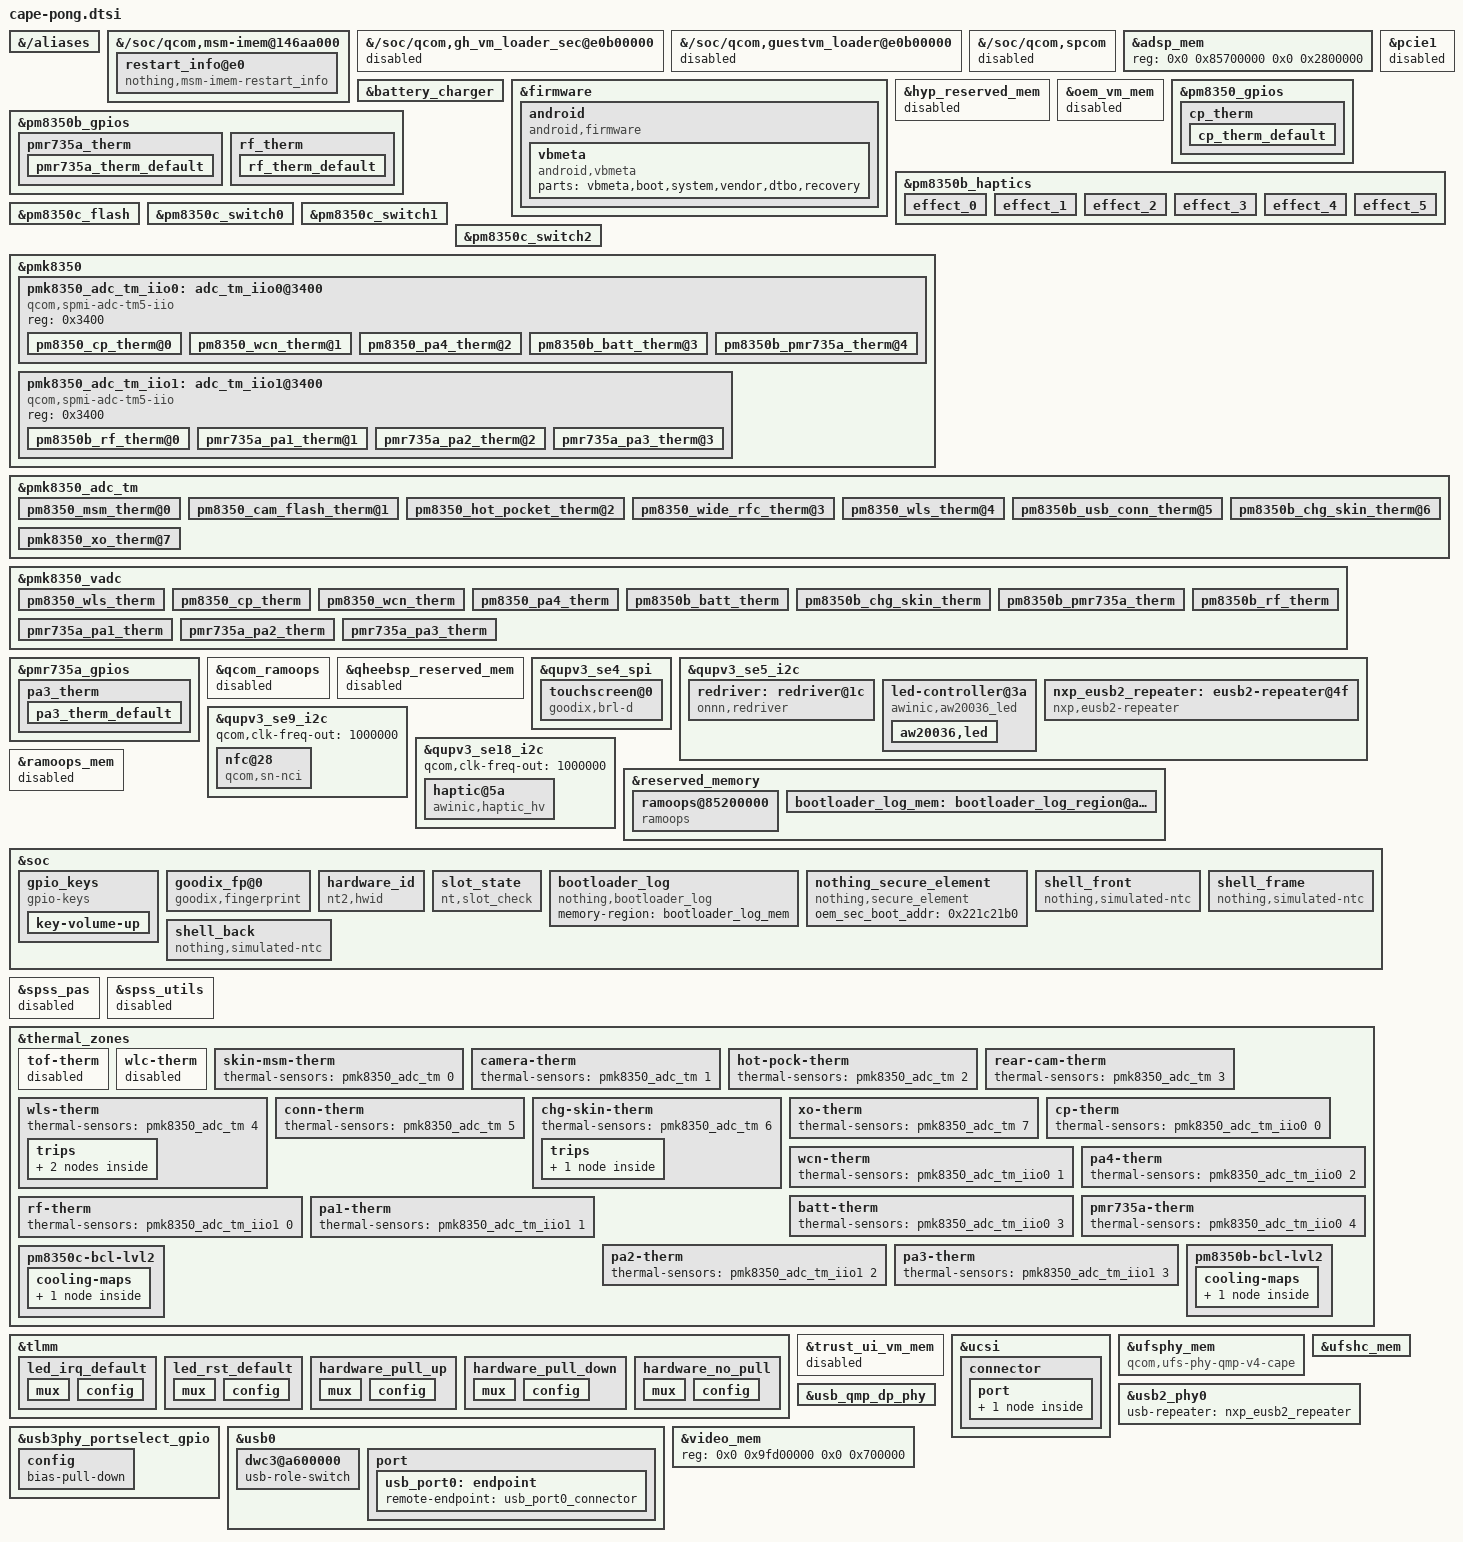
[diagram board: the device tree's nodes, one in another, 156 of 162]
// SPDX-License-Identifier: BSD-3-Clause
// SPDX-FileCopyrightText: 2026 The PenguinOS Project

#include <dt-bindings/gpio/gpio.h>
#include <dt-bindings/input/input.h>
#include <dt-bindings/phy/qcom,usb3-4nm-qmp-combo.h>

#include "cape-pmic-overlay.dtsi"
#include "waipio-pm8010-spmi.dtsi"
#include "waipio-thermal-overlay.dtsi"

#include "cape-pong-regulators.dtsi"

&{/aliases} {
	i2c0 = "/soc/qcom,qupv3_0_geni_se@9c0000/i2c@994000";
	i2c1 = "/soc/qcom,qupv3_1_geni_se@ac0000/i2c@a84000";
	i2c2 = "/soc/qcom,qupv3_1_geni_se@ac0000/i2c@a94000";
	i2c3 = "/soc/qcom,qupv3_2_geni_se@8c0000/i2c@88c000";
};

&{/soc/qcom,msm-imem@146aa000} {
	restart_info@e0 {
		compatible = "nothing,msm-imem-restart_info";
		reg = <0xe0 0x64>;
		info_size = <0x64>;
	};
};

/* No trusted UI VM on this board; its carveout is gone too */
&{/soc/qcom,gh_vm_loader_sec@e0b00000} {
	status = "disabled";
};

&{/soc/qcom,guestvm_loader@e0b00000} {
	status = "disabled";
};

&{/soc/qcom,spcom} {
	status = "disabled";
};

&adsp_mem {
	reg = <0x0 0x85700000 0x0 0x2800000>;
};

&battery_charger {
	qcom,thermal-mitigation = <9000000 8500000 8000000 7500000 7000000
				   6500000 6000000 5500000 5000000 4500000
				   4000000 3500000 3000000 2500000 2400000
				   2000000 1600000 1500000 1200000 1000000
				   500000 0>;
	qcom,wireless-fw-name = "idt9415.bin";
	#cooling-cells = <2>;
};

&firmware {
	android {
		compatible = "android,firmware";

		vbmeta {
			compatible = "android,vbmeta";
			parts = "vbmeta,boot,system,vendor,dtbo,recovery";
		};
	};
};

&hyp_reserved_mem {
	status = "disabled";
};

&oem_vm_mem {
	status = "disabled";
};

&pcie1 {
	status = "disabled";
};

&pm8350_gpios {
	cp_therm {
		cp_therm_default: cp_therm_default {
			pins = "gpio2";
			bias-high-impedance;
		};
	};
};

&pm8350b_gpios {
	pmr735a_therm {
		pmr735a_therm_default: pmr735a_therm_default {
			pins = "gpio3";
			bias-high-impedance;
		};
	};

	rf_therm {
		rf_therm_default: rf_therm_default {
			pins = "gpio4";
			bias-high-impedance;
		};
	};
};

&pm8350b_haptics {
	qcom,vmax-mv = <1300>;
	qcom,lra-period-us = <5880>;

	status = "okay";

	effect_0 {
		/* CLICK */
		qcom,wf-vmax-mv = <1800>;
		qcom,wf-pattern-period-us = <5880>;
	};

	effect_1 {
		/* DOUBLE_CLICK */
		qcom,wf-vmax-mv = <1800>;
		qcom,wf-pattern-period-us = <5880>;
	};

	effect_2 {
		/* TICK */
		qcom,wf-vmax-mv = <1800>;
		qcom,wf-pattern-period-us = <5880>;
	};

	effect_3 {
		/* THUD */
		qcom,wf-vmax-mv = <1800>;
		qcom,wf-pattern-period-us = <5880>;
	};

	effect_4 {
		/* POP */
		qcom,wf-vmax-mv = <1800>;
		qcom,wf-pattern-period-us = <5880>;
	};

	effect_5 {
		/* HEAVY CLICK */
		qcom,wf-vmax-mv = <1800>;
		qcom,wf-pattern-period-us = <5880>;
	};
};

&pm8350c_flash {
	status = "okay";
};

&pm8350c_switch0 {
	qcom,led-mask = <9>; /* Channels 1 & 4 */
	qcom,symmetry-en;
};

&pm8350c_switch1 {
	qcom,led-mask = <6>; /* Channels 2 & 3 */
	qcom,symmetry-en;
};

&pm8350c_switch2 {
	qcom,led-mask = <15>; /* All Channels */
	qcom,symmetry-en;
};

&pmk8350 {
	pmk8350_adc_tm_iio0: adc_tm_iio0@3400 {
		compatible = "qcom,spmi-adc-tm5-iio";
		reg = <0x3400>;
		#address-cells = <1>;
		#size-cells = <0>;
		#thermal-sensor-cells = <1>;

		pm8350_cp_therm@0 {
			reg = <0>;
			io-channels = <&pmk8350_vadc PM8350_ADC7_GPIO1_100K_PU>;
			qcom,ratiometric;
			qcom,hw-settle-time-us = <200>;
		};

		pm8350_wcn_therm@1 {
			reg = <1>;
			io-channels = <&pmk8350_vadc PM8350_ADC7_GPIO2_100K_PU>;
			qcom,ratiometric;
			qcom,hw-settle-time-us = <200>;
		};

		pm8350_pa4_therm@2 {
			reg = <2>;
			io-channels = <&pmk8350_vadc PM8350_ADC7_GPIO4_100K_PU>;
			qcom,ratiometric;
			qcom,hw-settle-time-us = <200>;
		};

		pm8350b_batt_therm@3 {
			reg = <3>;
			io-channels = <&pmk8350_vadc PM8350B_ADC7_AMUX_THM1_100K_PU>;
			qcom,ratiometric;
			qcom,hw-settle-time-us = <200>;
		};

		pm8350b_pmr735a_therm@4 {
			reg = <4>;
			io-channels = <&pmk8350_vadc PM8350B_ADC7_GPIO3_100K_PU>;
			qcom,ratiometric;
			qcom,hw-settle-time-us = <200>;
		};
	};

	pmk8350_adc_tm_iio1: adc_tm_iio1@3400 {
		compatible = "qcom,spmi-adc-tm5-iio";
		reg = <0x3400>;
		#address-cells = <1>;
		#size-cells = <0>;
		#thermal-sensor-cells = <1>;

		pm8350b_rf_therm@0 {
			reg = <0>;
			io-channels = <&pmk8350_vadc PM8350B_ADC7_GPIO4_100K_PU>;
			qcom,ratiometric;
			qcom,hw-settle-time-us = <200>;
		};

		pmr735a_pa1_therm@1 {
			reg = <1>;
			io-channels = <&pmk8350_vadc PMR735A_ADC7_GPIO1_100K_PU>;
			qcom,ratiometric;
			qcom,hw-settle-time-us = <200>;
		};

		pmr735a_pa2_therm@2 {
			reg = <2>;
			io-channels = <&pmk8350_vadc PMR735A_ADC7_GPIO2_100K_PU>;
			qcom,ratiometric;
			qcom,hw-settle-time-us = <200>;
		};

		pmr735a_pa3_therm@3 {
			reg = <3>;
			io-channels = <&pmk8350_vadc PMR735A_ADC7_GPIO3_100K_PU>;
			qcom,ratiometric;
			qcom,hw-settle-time-us = <200>;
		};
	};
};

/*
 * The ADC_TM5 driver wants reg to be the TM channel (0-7) and io-channels
 * per child, not the ADC channel number used by waipio-pmic-overlay.dtsi.
 */
&pmk8350_adc_tm {
	/delete-property/ io-channels;
	/delete-node/ pm8350_msm_therm;
	/delete-node/ pm8350_cam_flash_therm;
	/delete-node/ pm8350_hot_pocket_therm;
	/delete-node/ pm8350_wide_rfc_therm;
	/delete-node/ pm8350_rear_tof_therm;
	/delete-node/ pm8350b_usb_conn_therm;
	/delete-node/ pm8350b_wl_chg_therm;
	/delete-node/ pmk8350_xo_therm;

	pm8350_msm_therm@0 {
		reg = <0>;
		io-channels = <&pmk8350_vadc PM8350_ADC7_AMUX_THM1_100K_PU>;
		qcom,ratiometric;
		qcom,hw-settle-time-us = <200>;
	};

	pm8350_cam_flash_therm@1 {
		reg = <1>;
		io-channels = <&pmk8350_vadc PM8350_ADC7_AMUX_THM2_100K_PU>;
		qcom,ratiometric;
		qcom,hw-settle-time-us = <200>;
	};

	pm8350_hot_pocket_therm@2 {
		reg = <2>;
		io-channels = <&pmk8350_vadc PM8350_ADC7_AMUX_THM3_100K_PU>;
		qcom,ratiometric;
		qcom,hw-settle-time-us = <200>;
	};

	pm8350_wide_rfc_therm@3 {
		reg = <3>;
		io-channels = <&pmk8350_vadc PM8350_ADC7_AMUX_THM4_100K_PU>;
		qcom,ratiometric;
		qcom,hw-settle-time-us = <200>;
	};

	pm8350_wls_therm@4 {
		reg = <4>;
		io-channels = <&pmk8350_vadc PM8350_ADC7_AMUX_THM5_100K_PU>;
		qcom,ratiometric;
		qcom,hw-settle-time-us = <200>;
	};

	pm8350b_usb_conn_therm@5 {
		reg = <5>;
		io-channels = <&pmk8350_vadc PM8350B_ADC7_AMUX_THM4_100K_PU>;
		qcom,ratiometric;
		qcom,hw-settle-time-us = <200>;
	};

	pm8350b_chg_skin_therm@6 {
		reg = <6>;
		io-channels = <&pmk8350_vadc PM8350B_ADC7_GPIO2_100K_PU>;
		qcom,ratiometric;
		qcom,hw-settle-time-us = <200>;
	};

	pmk8350_xo_therm@7 {
		reg = <7>;
		io-channels = <&pmk8350_vadc PMK8350_ADC7_AMUX_THM1_100K_PU>;
		qcom,ratiometric;
		qcom,hw-settle-time-us = <200>;
	};
};

&pmk8350_vadc {
	pinctrl-0 = <&pm8350_rear_tof_therm_default &pmr735a_therm_default
		     &rf_therm_default &cp_therm_default &pa3_therm_default>;

	/delete-node/ pm8350_rear_tof_therm;
	/delete-node/ pm8350b_wl_chg_therm;

	pm8350_wls_therm {
		reg = <PM8350_ADC7_AMUX_THM5_100K_PU>;
		label = "pm8350_wls_therm";
		qcom,ratiometric;
		qcom,hw-settle-time = <200>;
		qcom,pre-scaling = <1 1>;
	};

	pm8350_cp_therm {
		reg = <PM8350_ADC7_GPIO1_100K_PU>;
		label = "pm8350_cp_therm";
		qcom,ratiometric;
		qcom,hw-settle-time = <200>;
		qcom,pre-scaling = <1 1>;
	};

	pm8350_wcn_therm {
		reg = <PM8350_ADC7_GPIO2_100K_PU>;
		label = "pm8350_wcn_therm";
		qcom,ratiometric;
		qcom,hw-settle-time = <200>;
		qcom,pre-scaling = <1 1>;
	};

	pm8350_pa4_therm {
		reg = <PM8350_ADC7_GPIO4_100K_PU>;
		label = "pm8350_pa4_therm";
		qcom,ratiometric;
		qcom,hw-settle-time = <200>;
		qcom,pre-scaling = <1 1>;
	};

	pm8350b_batt_therm {
		reg = <PM8350B_ADC7_AMUX_THM1_100K_PU>;
		label = "pm8350b_batt_therm";
		qcom,ratiometric;
		qcom,hw-settle-time = <200>;
		qcom,pre-scaling = <1 1>;
	};

	pm8350b_chg_skin_therm {
		reg = <PM8350B_ADC7_GPIO2_100K_PU>;
		label = "pm8350b_chg_skin_therm";
		qcom,ratiometric;
		qcom,hw-settle-time = <200>;
		qcom,pre-scaling = <1 1>;
	};

	pm8350b_pmr735a_therm {
		reg = <PM8350B_ADC7_GPIO3_100K_PU>;
		label = "pm8350b_pmr735a_therm";
		qcom,ratiometric;
		qcom,hw-settle-time = <200>;
		qcom,pre-scaling = <1 1>;
	};

	pm8350b_rf_therm {
		reg = <PM8350B_ADC7_GPIO4_100K_PU>;
		label = "pm8350b_rf_therm";
		qcom,ratiometric;
		qcom,hw-settle-time = <200>;
		qcom,pre-scaling = <1 1>;
	};

	pmr735a_pa1_therm {
		reg = <PMR735A_ADC7_GPIO1_100K_PU>;
		label = "pmr735a_pa1_therm";
		qcom,ratiometric;
		qcom,hw-settle-time = <200>;
		qcom,pre-scaling = <1 1>;
	};

	pmr735a_pa2_therm {
		reg = <PMR735A_ADC7_GPIO2_100K_PU>;
		label = "pmr735a_pa2_therm";
		qcom,ratiometric;
		qcom,hw-settle-time = <200>;
		qcom,pre-scaling = <1 1>;
	};

	pmr735a_pa3_therm {
		reg = <PMR735A_ADC7_GPIO3_100K_PU>;
		label = "pmr735a_pa3_therm";
		qcom,ratiometric;
		qcom,hw-settle-time = <200>;
		qcom,pre-scaling = <1 1>;
	};
};

&pmr735a_gpios {
	pa3_therm {
		pa3_therm_default: pa3_therm_default {
			pins = "gpio3";
			bias-high-impedance;
		};
	};
};

&qcom_ramoops {
	status = "disabled";
};

&qheebsp_reserved_mem {
	status = "disabled";
};

&qupv3_se4_spi {
	status = "okay";

	touchscreen@0 {
		compatible = "goodix,brl-d";
		reg = <0>;
		spi-max-frequency = <20000000>;

		goodix,avdd-name = "avdd";
		avdd-supply = <&L3C>;
		goodix,iovdd-name = "iovdd";
		iovdd-supply = <&L12C>;

		goodix,reset-gpio = <&tlmm 20 0x0>;
		goodix,irq-gpio = <&tlmm 21 0x2008>;
		goodix,irq-flags = <2>; /* 1: rising, 2: falling */
		goodix,panel-max-x = <1080>;
		goodix,panel-max-y = <2412>;
		goodix,panel-max-w = <255>;

		goodix,sleep-enable;
		goodix,firmware-name = "goodix_firmware.bin";
		goodix,config-name = "goodix_cfg_group.bin";
	};
};

&qupv3_se5_i2c {
	#address-cells = <1>;
	#size-cells = <0>;

	status = "okay";

	redriver: redriver@1c {
		compatible = "onnn,redriver";
		reg = <0x1c>;

		lane-channel-swap;

		eq = /bits/ 8 <
				/* Parameters for USB */
				0x4 0x4 0x4 0x4
				/* Parameters for DP */
				0x4 0x6 0x6 0x4>;
		flat-gain = /bits/ 8 <
				/* Parameters for USB */
				0x0 0x1 0x1 0x2
				/* Parameters for DP */
				0x0 0x3 0x3 0x0>;
		output-comp = /bits/ 8 <
				/* Parameters for USB */
				0x3 0x3 0x3 0x3
				/* Parameters for DP */
				0x3 0x3 0x3 0x3>;
		loss-match = /bits/ 8 <
				/* Parameters for USB */
				0x1 0x3 0x3 0x1
				/* Parameters for DP */
				0x3 0x3 0x3 0x3>;
	};

	led-controller@3a {
		compatible = "awinic,aw20036_led";
		reg = <0x3a>;

		pinctrl-0 = <&led_irq_default &led_rst_default>;
		pinctrl-names = "default";

		irq-gpio = <&tlmm 60 0>;
		reset-gpio = <&tlmm 44 0>;

		aw20036,led {
			aw20036,name = "led_strips";
			aw20036,imax = <1>;
			aw20036,brightness = <128>;
			aw20036,max_brightness = <255>;
		};
	};

	nxp_eusb2_repeater: eusb2-repeater@4f {
		compatible = "nxp,eusb2-repeater";
		reg = <0x4f>;

		pinctrl-0 = <&eusb2_reset_ctrl_default>;
		pinctrl-names = "default";

		reset-gpio = <&pm8350c_gpios 7 GPIO_ACTIVE_HIGH>;

		vdd1v8-supply = <&S10B>;
		vdd3v3-supply = <&L2B>;

		qcom,param-override-seq = <
			/* Rx squelch detection threshold to 110mV; default is 125mV */
			0x40 0x06
			/* Tx Deemphasis to 2dB, Tx Deemphasis bit duration to 0.8UI */
			0x22 0x07
			/* Output Voltage Swing to 550mV; default is 450mV */
			0x64 0x08
		>;
	};
};

&qupv3_se9_i2c {
	#address-cells = <1>;
	#size-cells = <0>;
	qcom,clk-freq-out = <1000000>;

	status = "okay";

	nfc@28 {
		compatible = "qcom,sn-nci";
		reg = <0x28>;

		pinctrl-0 = <&nfc_int_active &nfc_enable_active>;
		pinctrl-1 = <&nfc_int_suspend &nfc_enable_suspend>;
		pinctrl-names = "nfc_active", "nfc_suspend";

		interrupt-parent = <&tlmm>;
		interrupts = <46 0>;
		interrupt-names = "nfc_irq";

		qcom,sn-irq = <&tlmm 46 0x00>;
		qcom,sn-ven = <&tlmm 34 0x00>;
		qcom,sn-firm = <&tlmm 45 0x00>;
		qcom,sn-clkreq = <&tlmm 35 0x00>;

		qcom,sn-vdd-1p8-supply = <&S10B>;
		qcom,sn-vdd-1p8-voltage = <1800000 1800000>;
		qcom,sn-vdd-1p8-current = <157000>;
	};
};

&qupv3_se18_i2c {
	#address-cells = <1>;
	#size-cells = <0>;
	qcom,clk-freq-out = <1000000>;

	status = "okay";

	haptic@5a {
		compatible = "awinic,haptic_hv";
		reg = <0x5a>;

		irq-gpio = <&tlmm 51 0>;
		reset-gpio = <&tlmm 99 0>;

		f0_pre = <1700>;
		mode = /bits/ 8 <5>;
		f0_cali_percent = /bits/ 8 <7>;

		aw8692x_gain_bypass = /bits/ 8 <1>;
		aw8692x_cont_drv1_lvl = /bits/ 8 <0x7f>;
		aw8692x_cont_lra_vrms = <1000>; /* Motor rated voltage, mV */
		aw8692x_cont_drv1_time = /bits/ 8 <0x04>;
		aw8692x_cont_drv2_time = /bits/ 8 <0x06>;
		aw8692x_cont_wait_num = /bits/ 8 <0x06>;
		aw8692x_cont_brk_time = /bits/ 8 <0x08>;
		aw8692x_cont_track_margin = /bits/ 8 <0x0f>;
		aw8692x_brk_bst_md = /bits/ 8 <0>;
		aw8692x_cont_tset = /bits/ 8 <0x06>;
		aw8692x_cont_bemf_set = /bits/ 8 <0x02>;
		aw8692x_cont_bst_brk_gain = /bits/ 8 <0x05>;
		aw8692x_cont_brk_gain = /bits/ 8 <0x08>;
		aw8692x_duration_time = /bits/ 8 <20 30 60>;
		aw8692x_d2s_gain = /bits/ 8 <0x04>;
		aw8692x_trig_config = /bits/ 8 <0 0 0 1 0 2 0 0
						0 0 0 1 0 2 0 0
						0 0 0 1 0 2 0 0>;
		aw8692x_bst_vol_default = <9000>;
		aw8692x_is_enabled_track_en;
	};
};

&ramoops_mem {
	status = "disabled";
};

&reserved_memory {
	#address-cells = <2>;
	#size-cells = <2>;
	ranges;

	ramoops@85200000 {
		compatible = "ramoops";
		reg = <0x0 0x85200000 0x0 0x400000>;
		console-size = <0x200000>;
		pmsg-size = <0x200000>;
		mem-type = <0>;
		no-map;
	};

	bootloader_log_mem: bootloader_log_region@a7605000 {
		reg = <0x0 0xa7605000 0x0 0x8000>;
		no-map;
	};
};

&soc {
	gpio_keys {
		compatible = "gpio-keys";
		label = "gpio-keys";

		pinctrl-0 = <&key_vol_up_default>;
		pinctrl-names = "default";

		key-volume-up {
			label = "Volume Up";
			linux,code = <KEY_VOLUMEUP>;
			gpios = <&pm8350_gpios 6 GPIO_ACTIVE_LOW>;
			debounce-interval = <15>;
			linux,can-disable;
			wakeup-source;
		};
	};

	goodix_fp@0 {
		compatible = "goodix,fingerprint";

		interrupt-parent = <&tlmm>;

		vdd-supply = <&L9C>;
		vdd-max-uv = <3300000>;
		vdd-min-uv = <3300000>;

		fp-gpio-irq = <&tlmm 40 0x00>;
		fp-gpio-reset = <&tlmm 41 0x00>;
	};

	hardware_id {
		compatible = "nt2,hwid";

		pinctrl-0 = <&hardware_pull_up>;
		pinctrl-1 = <&hardware_pull_down>;
		pinctrl-2 = <&hardware_no_pull>;
		pinctrl-names = "hardware_up", "hardware_down", "hardware_lpm";

		ver_id0 = <&tlmm 87 0x00>;
		ver_id1 = <&tlmm 88 0x00>;
	};

	slot_state {
		compatible = "nt,slot_check";
		uim0_present = <&tlmm 133 0x00>;
		uim1_present = <&tlmm 137 0x00>;
	};

	bootloader_log {
		compatible = "nothing,bootloader_log";
		memory-region = <&bootloader_log_mem>;
	};

	nothing_secure_element {
		compatible = "nothing,secure_element";
		/* 0x221c01b0 + 0x2000 */
		oem_sec_boot_addr = <0x221c21b0>;
	};

	shell_front {
		compatible = "nothing,simulated-ntc";
	};

	shell_frame {
		compatible = "nothing,simulated-ntc";
	};

	shell_back {
		compatible = "nothing,simulated-ntc";
	};
};

&spss_pas {
	status = "disabled";
};

&spss_utils {
	status = "disabled";
};

&thermal_zones {
	/* Replaced by wls-therm and chg-skin-therm */
	tof-therm {
		status = "disabled";
	};

	wlc-therm {
		status = "disabled";
	};

	skin-msm-therm {
		thermal-sensors = <&pmk8350_adc_tm 0>;
	};

	camera-therm {
		thermal-sensors = <&pmk8350_adc_tm 1>;
	};

	hot-pock-therm {
		thermal-sensors = <&pmk8350_adc_tm 2>;
	};

	rear-cam-therm {
		thermal-sensors = <&pmk8350_adc_tm 3>;
	};

	wls-therm {
		thermal-sensors = <&pmk8350_adc_tm 4>;

		trips {
			active-config0 {
				temperature = <125000>;
				hysteresis = <1000>;
				type = "passive";
			};

			active-config1 {
				temperature = <125000>;
				hysteresis = <1000>;
				type = "passive";
			};
		};
	};

	conn-therm {
		thermal-sensors = <&pmk8350_adc_tm 5>;
	};

	chg-skin-therm {
		thermal-sensors = <&pmk8350_adc_tm 6>;

		trips {
			active-config0 {
				temperature = <125000>;
				hysteresis = <1000>;
				type = "passive";
			};
		};
	};

	xo-therm {
		thermal-sensors = <&pmk8350_adc_tm 7>;
	};

	cp-therm {
		thermal-sensors = <&pmk8350_adc_tm_iio0 0>;
	};

	wcn-therm {
		thermal-sensors = <&pmk8350_adc_tm_iio0 1>;
	};

	pa4-therm {
		thermal-sensors = <&pmk8350_adc_tm_iio0 2>;
	};

	batt-therm {
		thermal-sensors = <&pmk8350_adc_tm_iio0 3>;
	};

	pmr735a-therm {
		thermal-sensors = <&pmk8350_adc_tm_iio0 4>;
	};

	rf-therm {
		thermal-sensors = <&pmk8350_adc_tm_iio1 0>;
	};

	pa1-therm {
		thermal-sensors = <&pmk8350_adc_tm_iio1 1>;
	};

	pa2-therm {
		thermal-sensors = <&pmk8350_adc_tm_iio1 2>;
	};

	pa3-therm {
		thermal-sensors = <&pmk8350_adc_tm_iio1 3>;
	};

	pm8350b-bcl-lvl2 {
		cooling-maps {
			vbat_gpu2 {
				cooling-device = <&msm_gpu 9 9>;
			};
		};
	};

	pm8350c-bcl-lvl2 {
		cooling-maps {
			vph_gpu2 {
				cooling-device = <&msm_gpu 9 9>;
			};
		};
	};
};

&tlmm {
	led_irq_default: led_irq_default {
		mux {
			pins = "gpio60";
			function = "gpio";
		};

		config {
			pins = "gpio60";
			drive-strength = <8>;
			bias-pull-up;
		};
	};

	led_rst_default: led_rst_default {
		mux {
			pins = "gpio44";
			function = "gpio";
		};

		config {
			pins = "gpio44";
			drive-strength = <8>;
			bias-disable;
		};
	};

	hardware_pull_up: hardware_pull_up {
		mux {
			pins = "gpio87", "gpio88";
			function = "gpio";
		};

		config {
			pins = "gpio87", "gpio88";
			drive-strength = <2>;
			bias-pull-up;
		};
	};

	hardware_pull_down: hardware_pull_down {
		mux {
			pins = "gpio87", "gpio88";
			function = "gpio";
		};

		config {
			pins = "gpio87", "gpio88";
			drive-strength = <2>;
			bias-pull-down;
		};
	};

	hardware_no_pull: hardware_no_pull {
		mux {
			pins = "gpio87", "gpio88";
			function = "gpio";
		};

		config {
			pins = "gpio87", "gpio88";
			drive-strength = <2>;
			bias-disable;
		};
	};
};

&trust_ui_vm_mem {
	status = "disabled";
};

&ucsi {
	connector {
		port {
			usb_port0_connector: endpoint {
				remote-endpoint = <&usb_port0>;
			};
		};
	};
};

&ufsphy_mem {
	compatible = "qcom,ufs-phy-qmp-v4-cape";

	vdda-phy-supply = <&L5B>;
	vdda-pll-supply = <&L10C>;
	vdda-phy-max-microamp = <197000>;
	vdda-pll-max-microamp = <23700>;

	status = "okay";
};

&ufshc_mem {
	vdd-hba-supply = <&gcc_ufs_phy_gdsc>;

	vcc-supply = <&L7B>;
	vcc-max-microamp = <1100000>;

	vccq-supply = <&L9B>;
	vccq-max-microamp = <1200000>;

	qcom,vddp-ref-clk-supply = <&L9B>;
	qcom,vddp-ref-clk-max-microamp = <100>;

	/* HS-G4 needs the turbo core/unipro/ice clocks on cape */
	freq-table-hz =
		<75000000 850000000>,
		<0 0>,
		<0 0>,
		<75000000 850000000>,
		<75000000 850000000>,
		<0 0>,
		<0 0>,
		<0 0>,
		<0 0>;

	status = "okay";
};

&usb2_phy0 {
	usb-repeater = <&nxp_eusb2_repeater>;
};

&usb3phy_portselect_gpio {
	config {
		bias-pull-down;
	};
};

&usb_qmp_dp_phy {
	pinctrl-names = "unused";

	qcom,qmp-phy-override-seq = <
		USB3_DP_QSERDES_RXA_RX_MODE_01_HIGH4 0x0D
		USB3_DP_QSERDES_TXB_TX_DRV_LVL 0x38
		USB3_DP_QSERDES_RXB_RX_MODE_01_HIGH4 0x0D
	>;
};

&usb0 {
	pinctrl-names = "default";
	pinctrl-0 = <&usb3phy_portselect_gpio>;

	gpios = <&tlmm 91 GPIO_ACTIVE_HIGH>;

	ssusb_redriver = <&redriver>;
	usb-role-switch;

	dwc3@a600000 {
		usb-role-switch;
	};

	port {
		usb_port0: endpoint {
			remote-endpoint = <&usb_port0_connector>;
		};
	};
};

&video_mem {
	reg = <0x0 0x9fd00000 0x0 0x700000>;
};

/* TODO: wlan (use-nv-mac) once the cnss techpack devicetree is in */
